# nrf7120E_enga_application register map
Vendor: Nordic Semiconductor; Series: nrf71; File version: 1
CPU: CM33 r0p4, little endian, MPU, FPU, 3 interrupt priority bits, 270 interrupts, 4 SAU regions
Registers are 32-bit, read-write, reset 0x0 unless marked. A register's access mark holds for its fields unless they carry their own. Offsets are from the block's base; [hi:lo] are bit positions; lines under a group give offsets from that group; 'fields as' and 'values as' point back to an identical list.

## GLOBAL_CLOCK_NS — Clock management 0
Base 0x4010E000
Same registers: GLOBAL_CLOCK_S 0x5010E000
0x00 TASKS_XOSTART wo — Start crystal oscillator (HFXO)
  [0] TASKS_XOSTART
    1=Trigger task
0x04 TASKS_XOSTOP wo — Stop crystal oscillator (HFXO)
  [0] TASKS_XOSTOP
    1=Trigger task
0x08 TASKS_PLLSTART wo — Start PLL and keep it running, regardless of the automatic clock requests
  [0] TASKS_PLLSTART
    1=Trigger task
0x0C TASKS_PLLSTOP wo — Stop PLL
  [0] TASKS_PLLSTOP
    1=Trigger task
0x10 TASKS_LFCLKSTART wo — Start LFCLK source as selected in LFCLK.SRC
  [0] TASKS_LFCLKSTART
    1=Trigger task
0x14 TASKS_LFCLKSTOP wo — Stop LFCLK source
  [0] TASKS_LFCLKSTOP
    1=Trigger task
0x24 TASKS_XO24MSTART wo — Request HFXO to provide a crystal clock for PCLK24M
  [0] TASKS_XO24MSTART
    1=Trigger task
0x28 TASKS_XO24MSTOP wo — Stop request HFXO for PCLK24M. When all requests for HFXO are stopped, HFXO will also stop.
  [0] TASKS_XO24MSTOP
    1=Trigger task
0x40 TASKS_AUXPLLSTART wo — Start AUXPLL audio clock source
  [0] TASKS_AUXPLLSTART
    1=Trigger task
0x44 TASKS_AUXPLLSTOP wo — Stop AUXPLL audio clock source
  [0] TASKS_AUXPLLSTOP
    1=Trigger task
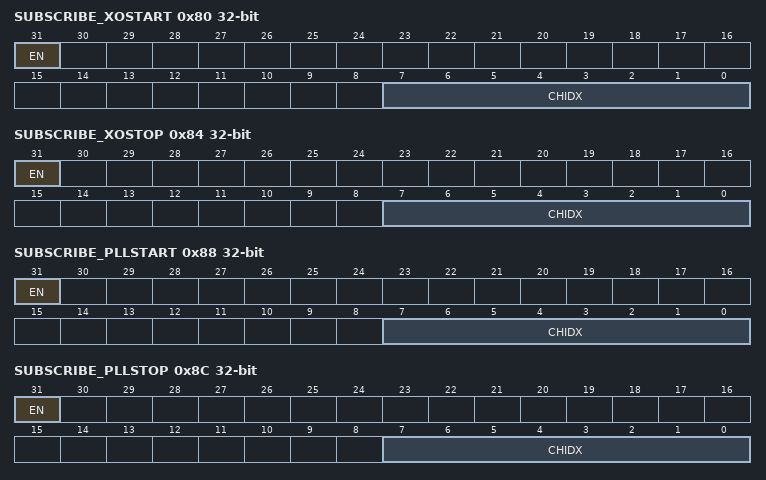
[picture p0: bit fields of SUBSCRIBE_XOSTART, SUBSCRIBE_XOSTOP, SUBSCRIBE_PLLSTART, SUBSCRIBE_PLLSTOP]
0x80 SUBSCRIBE_XOSTART — Subscribe configuration for task XOSTART
  [31] EN
    0=Disabled (Disable subscription); 1=Enabled (Enable subscription)
  [7:0] CHIDX — DPPI channel that task XOSTART will subscribe to
0x84 SUBSCRIBE_XOSTOP — Subscribe configuration for task XOSTOP
  [31] EN
    values as SUBSCRIBE_XOSTART.EN
  [7:0] CHIDX — DPPI channel that task XOSTOP will subscribe to
0x88 SUBSCRIBE_PLLSTART — Subscribe configuration for task PLLSTART
  [31] EN
    values as SUBSCRIBE_XOSTART.EN
  [7:0] CHIDX — DPPI channel that task PLLSTART will subscribe to
0x8C SUBSCRIBE_PLLSTOP — Subscribe configuration for task PLLSTOP
  [31] EN
    values as SUBSCRIBE_XOSTART.EN
  [7:0] CHIDX — DPPI channel that task PLLSTOP will subscribe to
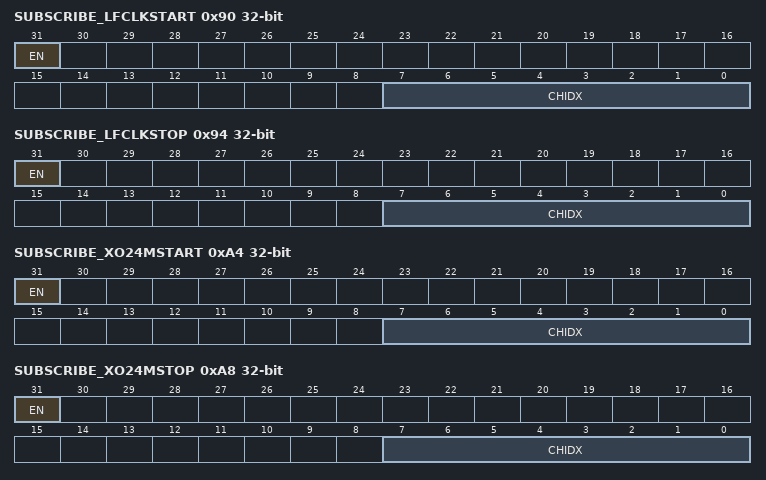
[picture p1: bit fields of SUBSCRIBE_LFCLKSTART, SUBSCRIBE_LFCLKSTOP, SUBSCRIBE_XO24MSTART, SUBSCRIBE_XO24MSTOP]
0x90 SUBSCRIBE_LFCLKSTART — Subscribe configuration for task LFCLKSTART
  [31] EN
    values as SUBSCRIBE_XOSTART.EN
  [7:0] CHIDX — DPPI channel that task LFCLKSTART will subscribe to
0x94 SUBSCRIBE_LFCLKSTOP — Subscribe configuration for task LFCLKSTOP
  [31] EN
    values as SUBSCRIBE_XOSTART.EN
  [7:0] CHIDX — DPPI channel that task LFCLKSTOP will subscribe to
0xA4 SUBSCRIBE_XO24MSTART — Subscribe configuration for task XO24MSTART
  [31] EN
    values as SUBSCRIBE_XOSTART.EN
  [7:0] CHIDX — DPPI channel that task XO24MSTART will subscribe to
0xA8 SUBSCRIBE_XO24MSTOP — Subscribe configuration for task XO24MSTOP
  [31] EN
    values as SUBSCRIBE_XOSTART.EN
  [7:0] CHIDX — DPPI channel that task XO24MSTOP will subscribe to
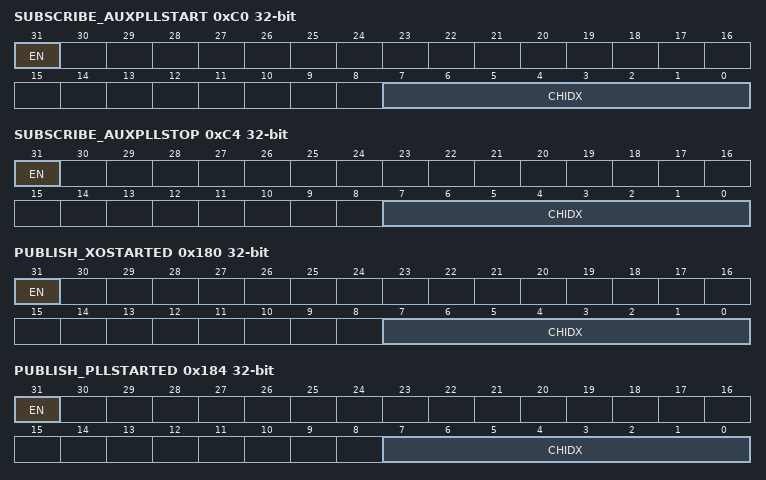
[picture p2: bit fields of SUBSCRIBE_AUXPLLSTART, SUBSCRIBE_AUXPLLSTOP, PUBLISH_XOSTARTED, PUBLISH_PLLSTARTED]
0xC0 SUBSCRIBE_AUXPLLSTART — Subscribe configuration for task AUXPLLSTART
  [31] EN
    values as SUBSCRIBE_XOSTART.EN
  [7:0] CHIDX — DPPI channel that task AUXPLLSTART will subscribe to
0xC4 SUBSCRIBE_AUXPLLSTOP — Subscribe configuration for task AUXPLLSTOP
  [31] EN
    values as SUBSCRIBE_XOSTART.EN
  [7:0] CHIDX — DPPI channel that task AUXPLLSTOP will subscribe to
0x100 EVENTS_XOSTARTED — Crystal oscillator has started
  [0] EVENTS_XOSTARTED
    0=NotGenerated (Event not generated); 1=Generated (Event generated)
0x104 EVENTS_PLLSTARTED — PLL started
  [0] EVENTS_PLLSTARTED
    values as EVENTS_XOSTARTED.EVENTS_XOSTARTED
0x108 EVENTS_LFCLKSTARTED — LFCLK source started
  [0] EVENTS_LFCLKSTARTED
    values as EVENTS_XOSTARTED.EVENTS_XOSTARTED
0x11C EVENTS_XO24MSTARTED — XO24M started
  [0] EVENTS_XO24MSTARTED
    values as EVENTS_XOSTARTED.EVENTS_XOSTARTED
0x120 EVENTS_AUXPLLSTARTED — AUXPLL source started
  [0] EVENTS_AUXPLLSTARTED
    values as EVENTS_XOSTARTED.EVENTS_XOSTARTED
0x180 PUBLISH_XOSTARTED — Publish configuration for event XOSTARTED
  [31] EN
    0=Disabled (Disable publishing); 1=Enabled (Enable publishing)
  [7:0] CHIDX — DPPI channel that event XOSTARTED will publish to
0x184 PUBLISH_PLLSTARTED — Publish configuration for event PLLSTARTED
  [31] EN
    values as PUBLISH_XOSTARTED.EN
  [7:0] CHIDX — DPPI channel that event PLLSTARTED will publish to
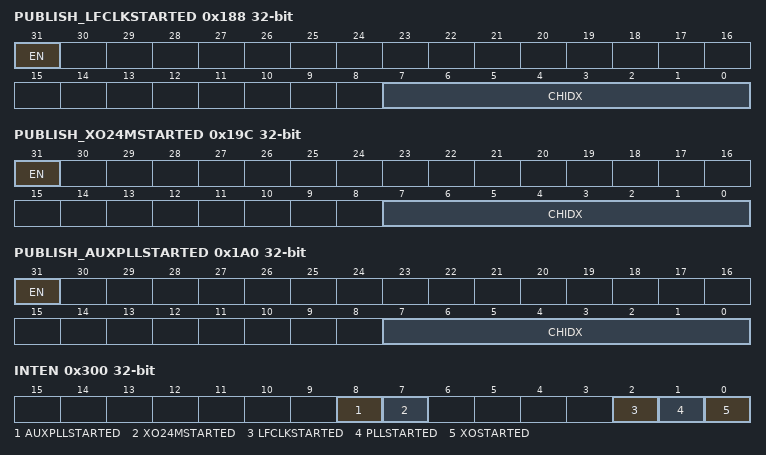
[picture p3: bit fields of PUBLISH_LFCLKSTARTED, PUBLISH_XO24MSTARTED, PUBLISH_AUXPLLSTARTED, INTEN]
0x188 PUBLISH_LFCLKSTARTED — Publish configuration for event LFCLKSTARTED
  [31] EN
    values as PUBLISH_XOSTARTED.EN
  [7:0] CHIDX — DPPI channel that event LFCLKSTARTED will publish to
0x19C PUBLISH_XO24MSTARTED — Publish configuration for event XO24MSTARTED
  [31] EN
    values as PUBLISH_XOSTARTED.EN
  [7:0] CHIDX — DPPI channel that event XO24MSTARTED will publish to
0x1A0 PUBLISH_AUXPLLSTARTED — Publish configuration for event AUXPLLSTARTED
  [31] EN
    values as PUBLISH_XOSTARTED.EN
  [7:0] CHIDX — DPPI channel that event AUXPLLSTARTED will publish to
0x300 INTEN — Enable or disable interrupt
  [all] fields
    0=Disabled; 1=Enabled
  [8] AUXPLLSTARTED — Enable or disable interrupt for event AUXPLLSTARTED
  [7] XO24MSTARTED — Enable or disable interrupt for event XO24MSTARTED
  [2] LFCLKSTARTED — Enable or disable interrupt for event LFCLKSTARTED
  [1] PLLSTARTED — Enable or disable interrupt for event PLLSTARTED
  [0] XOSTARTED — Enable or disable interrupt for event XOSTARTED
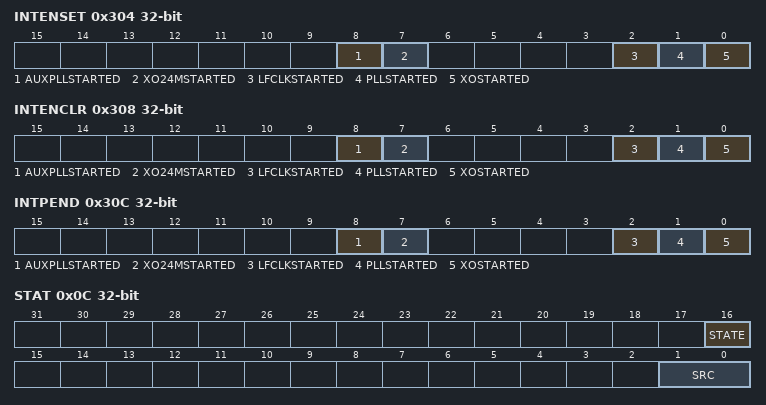
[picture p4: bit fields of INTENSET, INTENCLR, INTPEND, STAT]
0x304 INTENSET — Enable interrupt
  [all] fields
    on read: 0=Disabled (Read: Disabled); 1=Enabled (Read: Enabled) | on write: 1=Set (Enable)
  [8] AUXPLLSTARTED write-1-sets — Write '1' to enable interrupt for event AUXPLLSTARTED
  [7] XO24MSTARTED write-1-sets — Write '1' to enable interrupt for event XO24MSTARTED
  [2] LFCLKSTARTED write-1-sets — Write '1' to enable interrupt for event LFCLKSTARTED
  [1] PLLSTARTED write-1-sets — Write '1' to enable interrupt for event PLLSTARTED
  [0] XOSTARTED write-1-sets — Write '1' to enable interrupt for event XOSTARTED
0x308 INTENCLR — Disable interrupt
  [all] fields
    on read: 0=Disabled (Read: Disabled); 1=Enabled (Read: Enabled) | on write: 1=Clear (Disable)
  [8] AUXPLLSTARTED write-1-clears — Write '1' to disable interrupt for event AUXPLLSTARTED
  [7] XO24MSTARTED write-1-clears — Write '1' to disable interrupt for event XO24MSTARTED
  [2] LFCLKSTARTED write-1-clears — Write '1' to disable interrupt for event LFCLKSTARTED
  [1] PLLSTARTED write-1-clears — Write '1' to disable interrupt for event PLLSTARTED
  [0] XOSTARTED write-1-clears — Write '1' to disable interrupt for event XOSTARTED
0x30C INTPEND ro — Pending interrupts
  [all] fields
    on read: 0=NotPending (Read: Not pending); 1=Pending (Read: Pending)
  [8] AUXPLLSTARTED — Read pending status of interrupt for event AUXPLLSTARTED
  [7] XO24MSTARTED — Read pending status of interrupt for event XO24MSTARTED
  [2] LFCLKSTARTED — Read pending status of interrupt for event LFCLKSTARTED
  [1] PLLSTARTED — Read pending status of interrupt for event PLLSTARTED
  [0] XOSTARTED — Read pending status of interrupt for event XOSTARTED
0x400 XO group — Unspecified
  0x08 RUN ro — Indicates that XOSTART task was triggered
    [0] STATUS — XOSTART task triggered or not
      0=NotTriggered (Task not triggered); 1=Triggered (Task triggered)
  0x0C STAT ro — XO status
    [16] STATE — XO state (Running between START task and STOPPED event)
      0=NotRunning (XO is not running); 1=Running (XO is running)
0x420 PLL group — Unspecified
  0x08 RUN ro — Indicates that PLLSTART task was triggered
    [0] STATUS — PLLSTART task triggered or not
      values as XO.RUN.STATUS
  0x0C STAT ro — Which PLL settings were selected when triggering START task
    [16] STATE — PLL state (Running between START task and STOPPED event)
      0=NotRunning (PLL is not running); 1=Running (PLL is running)
0x440 LFCLK group — Unspecified
  0x00 SRC — Clock source for LFCLK
    [1:0] SRC — Select which LFCLK source is started by the LFCLKSTART task
      0=LFRC (32.768 kHz RC oscillator); 1=LFXO (32.768 kHz crystal oscillator); 2=LFSYNT (32.768 kHz synthesized from HFCLK)
  0x08 RUN ro — Indicates that LFCLKSTART task was triggered
    [0] STATUS — LFCLKSTART task triggered or not
      values as XO.RUN.STATUS
  0x0C STAT ro — Copy of LFCLK.SRCCOPY register, set when LFCLKSTARTED event is triggered.
    [16] STATE — LFCLK state (Running between START task and STOPPED event)
      0=NotRunning (LFCLK not running); 1=Running (LFCLK running)
    [1:0] SRC — Value of LFCLK.SRCCOPY register when LFCLKSTARTED event was triggered
      values as LFCLK.SRC.SRC
  0x10 SRCCOPY — Copy of LFCLK.SRC register, set when LFCLKSTART task is triggered
    [1:0] SRC — Value of LFCLK.SRC register when LFCLKSTART task was triggered
      values as LFCLK.SRC.SRC
0x460 PLL24M group — Unspecified
  0x08 RUN ro — Indicates that XO24MSTART task was triggered
    [0] STATUS — XO24MSTART task triggered or not
      values as XO.RUN.STATUS
  0x0C STAT ro — Which PLL settings were selected when triggering START task
    [16] STATE — PLL state (Running between START task and STOPPED event)
      0=NotRunning (PLL24M is not running); 1=Running (PLL24M is running)
0x480 AUXPLL group — Unspecified
  0x08 RUN ro — Indicates that AUXPLLSTART task was triggered
    [0] STATUS — AUXPLLSTART task triggered or not
      values as XO.RUN.STATUS
  0x0C STAT ro — Which AUXPLL settings were selected when triggering START task
    [16] STATE — AUXPLL state (Running between START task and STOPPED event)
      0=NotRunning (AUXPLL is not running); 1=Running (AUXPLL is running)
